# R40 register map
Vendor: Allwinner; Series: R40; File version: 0.1
CPU: CA7 0, little endian, MPU, FPU, double-precision FPU, 0 interrupt priority bits
Registers are 32-bit, read-write, reset 0x0 unless marked. A register's access mark holds for its fields unless they carry their own. Offsets are from the block's base; [hi:lo] are bit positions; {n}, {i} and the like mark numbered series.

## PIO
Base 0x01C20800
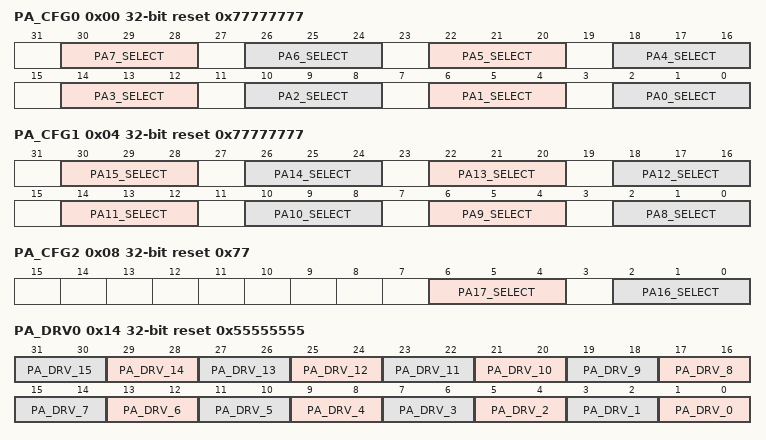
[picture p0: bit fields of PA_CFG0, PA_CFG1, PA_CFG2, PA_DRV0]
0x00 PA_CFG0 reset 0x77777777
  [30:28] PA7_SELECT — 000: Input 001: Output 010: ETXD0 011: SPI3_MOSI 100: Reserved 101: GTXD0 110: Reserved 111: IO Disable
    0=Input; 1=Output; 2=ETXD0; 3=SPI3_MOSI; 5=GTXD0; 7=IO (IO Disable)
  [26:24] PA6_SELECT — 000: Input 001: Output 010: ETXD1 011: SPI3_CLK 100: Reserved 101: GTXD1 110: Reserved 111: IO Disable
    0=Input; 1=Output; 2=ETXD1; 3=SPI3_CLK; 5=GTXD1; 7=IO (IO Disable)
  [22:20] PA5_SELECT — 000: Input 001: Output 010: ETXD2 011: SPI3_CS0 100: Reserved 101: GTXD2 110: Reserved 111: IO Disable
    0=Input; 1=Output; 2=ETXD2; 3=SPI3_CS0; 5=GTXD2; 7=IO (IO Disable)
  [18:16] PA4_SELECT — 000: Input 001: Output 010: ETXD3 011: SPI1_CS1 100: Reserved 101: GTXD3 110: Reserved 111: IO Disable
    0=Input; 1=Output; 2=ETXD3; 3=SPI1_CS1; 5=GTXD3; 7=IO (IO Disable)
  [14:12] PA3_SELECT — 000: Input 001: Output 010: ERXD0 011: SPI1_MISO 100: UART2_RX 101: GRXD0 110: Reserved 111: IO Disable
    0=Input; 1=Output; 2=ERXD0; 3=SPI1_MISO; 4=UART2_RX; 5=GRXD0; 7=IO (IO Disable)
  [10:8] PA2_SELECT — 000: Input 001: Output 010: ERXD1 011: SPI1_MOSI 100: UART2_TX 101: GRXD1 110: Reserved 111: IO Disable
    0=Input; 1=Output; 2=ERXD1; 3=SPI1_MOSI; 4=UART2_TX; 5=GRXD1; 7=IO (IO Disable)
  [6:4] PA1_SELECT — 000: Input 001: Output 010: ERXD2 011: SPI1_CLK 100: UART2_CTS 101: GRXD2 110: Reserved 111: IO Disable
    0=Input; 1=Output; 2=ERXD2; 3=SPI1_CLK; 4=UART2_CTS; 5=GRXD2; 7=IO (IO Disable)
  [2:0] PA0_SELECT — 000: Input 001: Output 010: ERXD3 011: SPI1_CS0 100: UART2_RTS 101: GRXD3 110: Reserved 111: IO Disable
    0=Input; 1=Output; 2=ERXD3; 3=SPI1_CS0; 4=UART2_RTS; 5=GRXD3; 7=IO (IO Disable)
0x04 PA_CFG1 reset 0x77777777
  [30:28] PA15_SELECT — 000: Input 001: Output 010: ECRS 011: UART7_RX 100: UART1_DSR 101: GTXCK/ECRS 110: I2S1_LRCK 111: IO Disable
    0=Input; 1=Output; 2=ECRS; 3=UART7_RX; 4=UART1_DSR; 5=GTXCK_slash_ECRS (GTXCK/ECRS); 6=I2S1_LRCK; 7=IO (IO Disable)
  [26:24] PA14_SELECT — 000: Input 001: Output 010: ETXCK 011: UART7_TX 100: UART1_DTR 101: GNULL/ETXCK 110: I2S1_BCLK 111: IO Disable
    0=Input; 1=Output; 2=ETXCK; 3=UART7_TX; 4=UART1_DTR; 5=GNULL_slash_ETXCK (GNULL/ETXCK); 6=I2S1_BCLK; 7=IO (IO Disable)
  [22:20] PA13_SELECT — 000: Input 001: Output 010: ETXEN 011: UART6_RX 100: UART1_CTS 101: GTXCTL/ETXEN 110: Reserved 111: IO Disable
    0=Input; 1=Output; 2=ETXEN; 3=UART6_RX; 4=UART1_CTS; 5=GTXCTL_slash_ETXEN (GTXCTL/ETXEN); 7=IO (IO Disable)
  [18:16] PA12_SELECT — 000: Input 001: Output 010: EMDIO 011: UART6_TX 100: UART1_RTS 101: GMDIO 110: Reserved 111: IO Disable
    0=Input; 1=Output; 2=EMDIO; 3=UART6_TX; 4=UART1_RTS; 5=GMDIO; 7=IO (IO Disable)
  [14:12] PA11_SELECT — 000: Input 001: Output 010: EMDC 011: Reserved 100: UART1_RX 101: GMDC 110: Reserved 111: IO Disable
    0=Input; 1=Output; 2=EMDC; 4=UART1_RX; 5=GMDC; 7=IO (IO Disable)
  [10:8] PA10_SELECT — 000: Input 001: Output 010: ERXDV 011: Reserved 100: UART1_TX 101: GRXCTL/ERXDV 110: Reserved 111: IO Disable
    0=Input; 1=Output; 2=ERXDV; 4=UART1_TX; 5=GRXCTL_slash_ERXDV (GRXCTL/ERXDV); 7=IO (IO Disable)
  [6:4] PA9_SELECT — 000: Input 001: Output 010: ERXERR 011: SPI3_CS1 100: Reserved 101: GNULL/ERXERR 110: I2S1_MCLK 111: IO Disable
    0=Input; 1=Output; 2=ERXERR; 3=SPI3_CS1; 5=GNULL_slash_ERXERR (GNULL/ERXERR); 6=I2S1_MCLK; 7=IO (IO Disable)
  [2:0] PA8_SELECT — 000: Input 001: Output 010: ERXCK 011: SPI3_MISO 100: Reserved 101: GRXCK 110: Reserved 111: IO Disable
    0=Input; 1=Output; 2=ERXCK; 3=SPI3_MISO; 5=GRXCK; 7=IO (IO Disable)
0x08 PA_CFG2 reset 0x77
  [6:4] PA17_SELECT — 000: Input 001: Output 010: ETXERR 011: Reserved 100: UART1_RING 101: GNULL/ETXERR 110: I2S1_DI 111: IO Disable
    0=Input; 1=Output; 2=ETXERR; 4=UART1_RING; 5=GNULL_slash_ETXERR (GNULL/ETXERR); 6=I2S1_DI; 7=IO (IO Disable)
  [2:0] PA16_SELECT — 000: Input 001: Output 010: ECOL 011: Reserved 100: UART1_DCD 101: GCLKIN/ECOL 110: I2S1_DO 111: IO Disable
    0=Input; 1=Output; 2=ECOL; 4=UART1_DCD; 5=GCLKIN_slash_ECOL (GCLKIN/ECOL); 6=I2S1_DO; 7=IO (IO Disable)
0x0C PA_CFG3 reset not defined
0x10 PA_DAT
  [17:0] PA_DAT — If the port is configured as input, the corresponding bit is the pin state. If the port is configured as output, the pin state is the same as the corresponding bit. The read bit value is the value setup by software. If the port is configured as functional pin, the undefined value will be read.
0x14 PA_DRV0 reset 0x55555555
  [2n+1:2n] PA_DRV_{n} (n=0..15) — PA[n] Multi-Driving Select (n = 0~15) 00: Level 0 01: Level 1 10: Level 2 11: Level 3
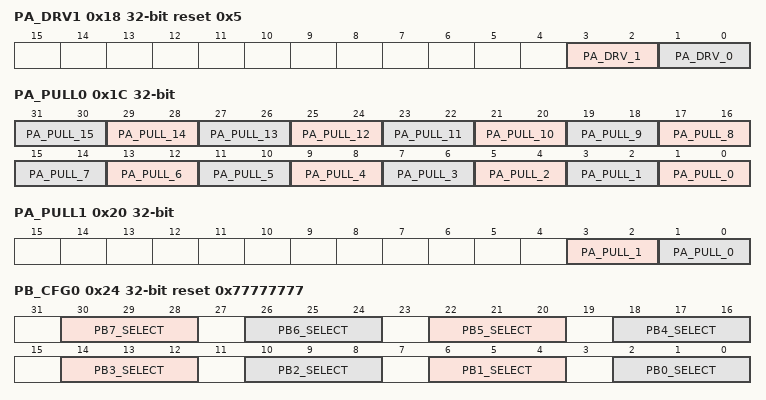
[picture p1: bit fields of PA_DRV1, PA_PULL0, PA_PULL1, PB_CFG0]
0x18 PA_DRV1 reset 0x5
  [3:2] PA_DRV_1 — PA[n] Multi-Driving Select (n = 16~17) 00: Level 0 01: Level 1 10: Level 2 11: Level 3
  [1:0] PA_DRV_0 — PA[n] Multi-Driving Select (n = 16~17) 00: Level 0 01: Level 1 10: Level 2 11: Level 3
0x1C PA_PULL0
  [2n+1:2n] PA_PULL_{n} (n=0..15) — PA[n] Pull-up/down Select (n = 0~15) 00: Pull-up/down disable 01: Pull-up 10: Pull-down 11: Reserved
0x20 PA_PULL1
  [3:2] PA_PULL_1 — PA[n] Pull-up/down Select (n = 16~17) 00: Pull-up/down disable 01: Pull-up enable 10: Pull-down 11: Reserved
  [1:0] PA_PULL_0 — PA[n] Pull-up/down Select (n = 16~17) 00: Pull-up/down disable 01: Pull-up enable 10: Pull-down 11: Reserved
0x24 PB_CFG0 reset 0x77777777
  [30:28] PB7_SELECT — 000: Input 001: Output 010: I2S_LRCK 011: AC97_SYNC 100: Reserved 101: Reserved 110: Reserved 111: IO Disable
    0=Input; 1=Output; 2=I2S_LRCK; 3=AC97_SYNC; 7=IO (IO Disable)
  [26:24] PB6_SELECT — 000: Input 001: Output 010: I2S_BCLK 011: AC97_BCLK 100: Reserved 101: Reserved 110: Reserved 111: IO Disable
    0=Input; 1=Output; 2=I2S_BCLK; 3=AC97_BCLK; 7=IO (IO Disable)
  [22:20] PB5_SELECT — 000: Input 001: Output 010: I2S_MCLK 011: AC97_MCLK 100: Reserved 101: Reserved 110: Reserved 111: IO Disable
    0=Input; 1=Output; 2=I2S_MCLK; 3=AC97_MCLK; 7=IO (IO Disable)
  [18:16] PB4_SELECT — 000: Input 001: Output 010: CIR0_RX 011: Reserved 100: Reserved 101: Reserved 110: Reserved 111: IO Disable
    0=Input; 1=Output; 2=CIR0_RX; 7=IO (IO Disable)
  [14:12] PB3_SELECT — 000: Input 001: Output 010: Reserved 011: PWM1 100: OWA_MCLK 101: Reserved 110: Reserved 111: IO Disable
    0=Input; 1=Output; 3=PWM1; 4=OWA_MCLK; 7=IO (IO Disable)
  [10:8] PB2_SELECT — 000: Input 001: Output 010: Reserved 011: PWM0 100: Reserved 101: Reserved 110: Reserved 111: IO Disable
    0=Input; 1=Output; 3=PWM0; 7=IO (IO Disable)
  [6:4] PB1_SELECT — 000: Input 001: Output 010: TWI0_SDA 011: Reserved 100: Reserved 101: Reserved 110: Reserved 111: IO Disable
    0=Input; 1=Output; 2=TWI0_SDA; 7=IO (IO Disable)
  [2:0] PB0_SELECT — 000: Input 001: Output 010: TWI0_SCK 011: PLL_LOCK_DBG 100: Reserved 101: Reserved 110: Reserved 111: IO Disable
    0=Input; 1=Output; 2=TWI0_SCK; 3=PLL_LOCK_DBG; 7=IO (IO Disable)
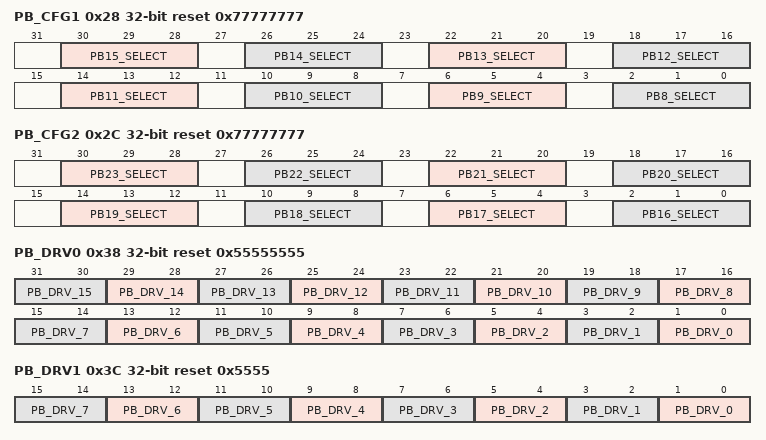
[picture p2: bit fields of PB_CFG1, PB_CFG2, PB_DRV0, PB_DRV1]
0x28 PB_CFG1 reset 0x77777777
  [30:28] PB15_SELECT — 000: Input 001: Output 010: SPI2_CLK 011: JTAG_CK0 100: Reserved 101: Reserved 110: Reserved 111: IO Disable
    0=Input; 1=Output; 2=SPI2_CLK; 3=JTAG_CK0; 7=IO (IO Disable)
  [26:24] PB14_SELECT — 000: Input 001: Output 010: SPI2_CS0 011: JTAG_MS0 100: Reserved 101: Reserved 110: Reserved 111: IO Disable
    0=Input; 1=Output; 2=SPI2_CS0; 3=JTAG_MS0; 7=IO (IO Disable)
  [22:20] PB13_SELECT — 000: Input 001: Output 010: SPI2_CS1 011: Reserved 100: OWA_DO 101: Reserved 110: Reserved 111: IO Disable
    0=Input; 1=Output; 2=SPI2_CS1; 4=OWA_DO; 7=IO (IO Disable)
  [18:16] PB12_SELECT — 000: Input 001: Output 010: I2S_DI 011: AC97_DI 100: Reserved 101: Reserved 110: Reserved 111: IO Disable
    0=Input; 1=Output; 2=I2S_DI; 3=AC97_DI; 7=IO (IO Disable)
  [14:12] PB11_SELECT — 000: Input 001: Output 010: I2S_DO3 011: Reserved 100: Reserved 101: Reserved 110: Reserved 111: IO Disable
    0=Input; 1=Output; 2=I2S_DO3; 7=IO (IO Disable)
  [10:8] PB10_SELECT — 000: Input 001: Output 010: I2S_DO2 011: Reserved 100: PWM7 101: Reserved 110: Reserved 111: IO Disable
    0=Input; 1=Output; 2=I2S_DO2; 4=PWM7; 7=IO (IO Disable)
  [6:4] PB9_SELECT — 000: Input 001: Output 010: I2S_DO1 011: Reserved 100: PWM6 101: Reserved 110: Reserved 111: IO Disable
    0=Input; 1=Output; 2=I2S_DO1; 4=PWM6; 7=IO (IO Disable)
  [2:0] PB8_SELECT — 000: Input 001: Output 010: I2S_DO0 011: AC97_DO 100: Reserved 101: Reserved 110: Reserved 111: IO Disable
    0=Input; 1=Output; 2=I2S_DO0; 3=AC97_DO; 7=IO (IO Disable)
0x2C PB_CFG2 reset 0x77777777
  [30:28] PB23_SELECT — 000: Input 001: Output 010: UART0_RX 011: CIR1_RX 100: Reserved 101: Reserved 110: Reserved 111: IO Disable
    0=Input; 1=Output; 2=UART0_RX; 3=CIR1_RX; 7=IO (IO Disable)
  [26:24] PB22_SELECT — 000: Input 001: Output 010: UART0_TX 011: Reserved 100: Reserved 101: Reserved 110: Reserved 111: IO Disable
    0=Input; 1=Output; 2=UART0_TX; 7=IO (IO Disable)
  [22:20] PB21_SELECT — 000: Input 001: Output 010: TWI2_SDA 011: Reserved 100: PWM5 101: Reserved 110: Reserved 111: IO Disable
    0=Input; 1=Output; 2=TWI2_SDA; 4=PWM5; 7=IO (IO Disable)
  [18:16] PB20_SELECT — 000: Input 001: Output 010: TWI2_SCK 011: Reserved 100: PWM4 101: Reserved 110: Reserved 111: IO Disable
    0=Input; 1=Output; 2=TWI2_SCK; 4=PWM4; 7=IO (IO Disable)
  [14:12] PB19_SELECT — 000: Input 001: Output 010: TWI1_SDA 011: Reserved 100: Reserved 101: Reserved 110: Reserved 111: IO Disable
    0=Input; 1=Output; 2=TWI1_SDA; 7=IO (IO Disable)
  [10:8] PB18_SELECT — 000: Input 001: Output 010: TWI1_SCK 011: Reserved 100: Reserved 101: Reserved 110: Reserved 111: IO Disable
    0=Input; 1=Output; 2=TWI1_SCK; 7=IO (IO Disable)
  [6:4] PB17_SELECT — 000: Input 001: Output 010: SPI2_MISO 011: JTAG_DI0 100: Reserved 101: Reserved 110: Reserved 111: IO Disable
    0=Input; 1=Output; 2=SPI2_MISO; 3=JTAG_DI0; 7=IO (IO Disable)
  [2:0] PB16_SELECT — 000: Input 001: Output 010: SPI2_MOSI 011: JTAG_DO0 100: Reserved 101: Reserved 110: Reserved 111: IO Disable
    0=Input; 1=Output; 2=SPI2_MOSI; 3=JTAG_DO0; 7=IO (IO Disable)
0x30 PB_CFG3 reset not defined
0x34 PB_DAT
  [23:0] PB_DAT — If the port is configured as input, the corresponding bit is the pin state. If the port is configured as output, the pin state is the same as the corresponding bit. The read bit value is the value setup by software. If the port is configured as functional pin, the undefined value will be read.
0x38 PB_DRV0 reset 0x55555555
  [2n+1:2n] PB_DRV_{n} (n=0..15) — PB[n] Multi-Driving Select (n = 0~15) 00: Level 0 01: Level 1 10: Level 2 11: Level 3
0x3C PB_DRV1 reset 0x5555
  [2n+1:2n] PB_DRV_{n} (n=0..7) — PB[n] Multi-Driving Select (n = 16~23) 00: Level 0 01: Level 1 10: Level 2 11: Level 3
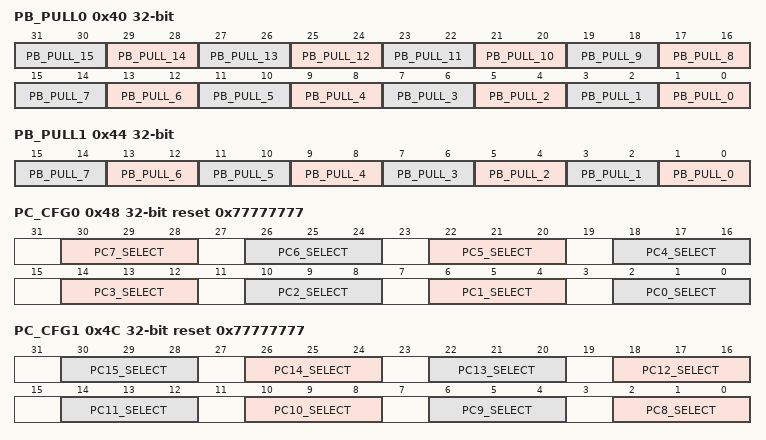
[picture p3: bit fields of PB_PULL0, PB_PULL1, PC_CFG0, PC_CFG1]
0x40 PB_PULL0
  [2n+1:2n] PB_PULL_{n} (n=0..15) — PB[n] Pull-up/down Select (n = 0~15) 00: Pull-up/down disable 01: Pull-up 10: Pull-down 11: Reserved
0x44 PB_PULL1
  [2n+1:2n] PB_PULL_{n} (n=0..7) — PB[n] Pull-up/down Select (n = 16~23) 00: Pull-up/down disable 01: Pull-up 10: Pull-down 11: Reserved
0x48 PC_CFG0 reset 0x77777777
  [30:28] PC7_SELECT — 000: Input 001: Output 010: NRB1 011: SDC2_CLK 100: Reserved 101: Reserved 110: Reserved 111: IO Disable
    0=Input; 1=Output; 2=NRB1; 3=SDC2_CLK; 7=IO (IO Disable)
  [26:24] PC6_SELECT — 000: Input 001: Output 010: NRB0 011: SDC2_CMD 100: Reserved 101: Reserved 110: Reserved 111: IO Disable
    0=Input; 1=Output; 2=NRB0; 3=SDC2_CMD; 7=IO (IO Disable)
  [22:20] PC5_SELECT — 000: Input 001: Output 010: NRE 011: SDC2_DS 100: Reserved 101: Reserved 110: Reserved 111: IO Disable
    0=Input; 1=Output; 2=NRE; 3=SDC2_DS; 7=IO (IO Disable)
  [18:16] PC4_SELECT — 000: Input 001: Output 010: NCE0 011: Reserved 100: Reserved 101: Reserved 110: Reserved 111: IO Disable
    0=Input; 1=Output; 2=NCE0; 7=IO (IO Disable)
  [14:12] PC3_SELECT — 000: Input 001: Output 010: NCE1 011: Reserved 100: Reserved 101: Reserved 110: Reserved 111: IO Disable
    0=Input; 1=Output; 2=NCE1; 7=IO (IO Disable)
  [10:8] PC2_SELECT — 000: Input 001: Output 010: NCLE 011: SPI0_CLK 100: Reserved 101: Reserved 110: Reserved 111: IO Disable
    0=Input; 1=Output; 2=NCLE; 3=SPI0_CLK; 7=IO (IO Disable)
  [6:4] PC1_SELECT — 000: Input 001: Output 010: NALE 011: SPI0_MISO 100: Reserved 101: Reserved 110: Reserved 111: IO Disable
    0=Input; 1=Output; 2=NALE; 3=SPI0_MISO; 7=IO (IO Disable)
  [2:0] PC0_SELECT — 000: Input 001: Output 010: NWE 011: SPI0_MOSI 100: Reserved 101: Reserved 110: Reserved 111: IO Disable
    0=Input; 1=Output; 2=NWE; 3=SPI0_MOSI; 7=IO (IO Disable)
0x4C PC_CFG1 reset 0x77777777
  [4n-30:4n-32] PC{n}_SELECT (n=8..15) — 000: Input 001: Output 010: NDQ{n-8} 011: SDC2_D{n-8} 100: Reserved 101: Reserved 110: Reserved 111: IO Disable
    0=Input; 1=Output; 2=NDQ{n-8}; 3=SDC2_D{n-8}; 7=IO (IO Disable)
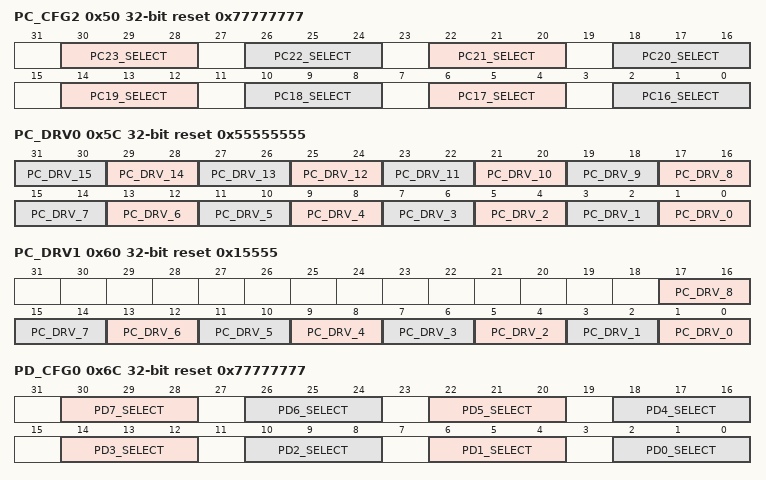
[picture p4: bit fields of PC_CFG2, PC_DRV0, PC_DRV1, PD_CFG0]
0x50 PC_CFG2 reset 0x77777777
  [30:28] PC23_SELECT — 000: Input 001: Output 010: Reserved 011: SPI0_CS0 100: Reserved 101: Reserved 110: Reserved 111: IO Disable
    0=Input; 1=Output; 3=SPI0_CS0; 7=IO (IO Disable)
  [26:24] PC22_SELECT — 000: Input 001: Output 010: NCE7 011: SPI2_MISO 100: Reserved 101: Reserved 110: Reserved 111: IO Disable
    0=Input; 1=Output; 2=NCE7; 3=SPI2_MISO; 7=IO (IO Disable)
  [22:20] PC21_SELECT — 000: Input 001: Output 010: NCE6 011: SPI2_MOSI 100: Reserved 101: Reserved 110: Reserved 111: IO Disable
    0=Input; 1=Output; 2=NCE6; 3=SPI2_MOSI; 7=IO (IO Disable)
  [18:16] PC20_SELECT — 000: Input 001: Output 010: NCE5 011: SPI2_CLK 100: Reserved 101: Reserved 110: Reserved 111: IO Disable
    0=Input; 1=Output; 2=NCE5; 3=SPI2_CLK; 7=IO (IO Disable)
  [14:12] PC19_SELECT — 000: Input 001: Output 010: NCE4 011: SPI2_CS0 100: Reserved 101: Reserved 110: Reserved 111: IO Disable
    0=Input; 1=Output; 2=NCE4; 3=SPI2_CS0; 7=IO (IO Disable)
  [10:8] PC18_SELECT — 000: Input 001: Output 010: NCE3 011: Reserved 100: Reserved 101: Reserved 110: Reserved 111: IO Disable
    0=Input; 1=Output; 2=NCE3; 7=IO (IO Disable)
  [6:4] PC17_SELECT — 000: Input 001: Output 010: NCE2 011: Reserved 100: Reserved 101: Reserved 110: Reserved 111: IO Disable
    0=Input; 1=Output; 2=NCE2; 7=IO (IO Disable)
  [2:0] PC16_SELECT — 000: Input 001: Output 010: NWP 011: Reserved 100: Reserved 101: Reserved 110: Reserved 111: IO Disable
    0=Input; 1=Output; 2=NWP; 7=IO (IO Disable)
0x54 PC_CFG3 reset 0x7
  [2:0] PC24_SELECT — 000: Input 001: Output 010: NDQS 011: SDC2_RST 100: Reserved 101: Reserved 110: Reserved 111: IO Disable
    0=Input; 1=Output; 2=NDQS; 3=SDC2_RST; 7=IO (IO Disable)
0x58 PC_DAT
  [23:0] PC_DAT — If the port is configured as input, the corresponding bit is the pin state. If the port is configured as output, the pin state is the same as the corresponding bit. The read bit value is the value setup by software. If the port is configured as functional pin, the undefined value will be read.
0x5C PC_DRV0 reset 0x55555555
  [2n+1:2n] PC_DRV_{n} (n=0..15) — PC[n] Multi-Driving Select (n = 0~15) 00: Level 0 01: Level 1 10: Level 2 11: Level 3
0x60 PC_DRV1 reset 0x15555
  [2n+1:2n] PC_DRV_{n} (n=0..8) — PC[n] Multi-Driving Select (n = 16~24) 00: Level 0 01: Level 1 10: Level 2 11: Level 3
0x64 PC_PULL0 reset not defined
0x68 PC_PULL1 reset not defined
0x6C PD_CFG0 reset 0x77777777
  [30:28] PD7_SELECT — 000: Input 001: Output 010: LCD0_D7 011: LVDS0_VNC 100: Reserved 101: Reserved 110: Reserved 111: IO Disable
    0=Input; 1=Output; 2=LCD0_D7; 3=LVDS0_VNC; 7=IO (IO Disable)
  [26:24] PD6_SELECT — 000: Input 001: Output 010: LCD0_D6 011: LVDS0_VPC 100: Reserved 101: Reserved 110: Reserved 111: IO Disable
    0=Input; 1=Output; 2=LCD0_D6; 3=LVDS0_VPC; 7=IO (IO Disable)
  [22:20] PD5_SELECT — 000: Input 001: Output 010: LCD0_D5 011: LVDS0_VN2 100: Reserved 101: Reserved 110: Reserved 111: IO Disable
    0=Input; 1=Output; 2=LCD0_D5; 3=LVDS0_VN2; 7=IO (IO Disable)
  [18:16] PD4_SELECT — 000: Input 001: Output 010: LCD0_D4 011: LVDS0_VP2 100: Reserved 101: Reserved 110: Reserved 111: IO Disable
    0=Input; 1=Output; 2=LCD0_D4; 3=LVDS0_VP2; 7=IO (IO Disable)
  [14:12] PD3_SELECT — 000: Input 001: Output 010: LCD0_D3 011: LVDS0_VN1 100: Reserved 101: Reserved 110: Reserved 111: IO Disable
    0=Input; 1=Output; 2=LCD0_D3; 3=LVDS0_VN1; 7=IO (IO Disable)
  [10:8] PD2_SELECT — 000: Input 001: Output 010: LCD0_D2 011: LVDS0_VP1 100: Reserved 101: Reserved 110: Reserved 111: IO Disable
    0=Input; 1=Output; 2=LCD0_D2; 3=LVDS0_VP1; 7=IO (IO Disable)
  [6:4] PD1_SELECT — 000: Input 001: Output 010: LCD0_D1 011: LVDS0_VN0 100: Reserved 101: Reserved 110: Reserved 111: IO Disable
    0=Input; 1=Output; 2=LCD0_D1; 3=LVDS0_VN0; 7=IO (IO Disable)
  [2:0] PD0_SELECT — 000: Input 001: Output 010: LCD0_D0 011: LVDS0_VP0 100: Reserved 101: Reserved 110: Reserved 111: IO Disable
    0=Input; 1=Output; 2=LCD0_D0; 3=LVDS0_VP0; 7=IO (IO Disable)
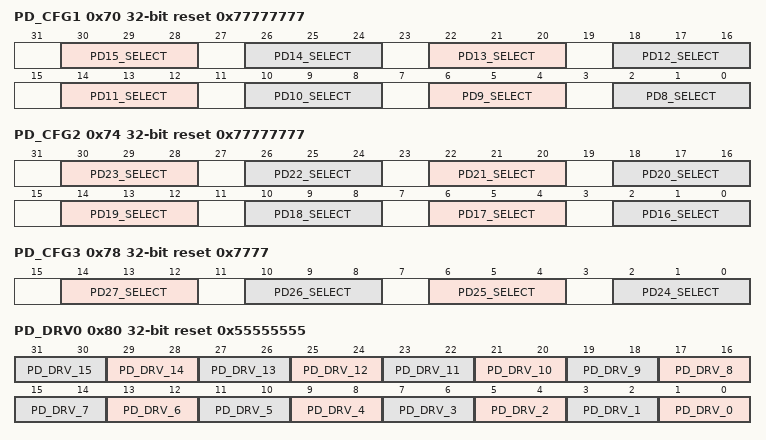
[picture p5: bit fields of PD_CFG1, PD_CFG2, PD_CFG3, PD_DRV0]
0x70 PD_CFG1 reset 0x77777777
  [30:28] PD15_SELECT — 000: Input 001: Output 010: LCD0_D15 011: LVDS1_VN2 100: Reserved 101: Reserved 110: Reserved 111: IO Disable
    0=Input; 1=Output; 2=LCD0_D15; 3=LVDS1_VN2; 7=IO (IO Disable)
  [26:24] PD14_SELECT — 000: Input 001: Output 010: LCD0_D14 011: LVDS1_VP2 100: Reserved 101: Reserved 110: Reserved 111: IO Disable
    0=Input; 1=Output; 2=LCD0_D14; 3=LVDS1_VP2; 7=IO (IO Disable)
  [22:20] PD13_SELECT — 000: Input 001: Output 010: LCD0_D13 011: LVDS1_VN1 100: Reserved 101: Reserved 110: Reserved 111: IO Disable
    0=Input; 1=Output; 2=LCD0_D13; 3=LVDS1_VN1; 7=IO (IO Disable)
  [18:16] PD12_SELECT — 000: Input 001: Output 010: LCD0_D12 011: LVDS1_VP1 100: Reserved 101: Reserved 110: Reserved 111: IO Disable
    0=Input; 1=Output; 2=LCD0_D12; 3=LVDS1_VP1; 7=IO (IO Disable)
  [14:12] PD11_SELECT — 000: Input 001: Output 010: LCD0_D11 011: LVDS1_VN0 100: Reserved 101: Reserved 110: Reserved 111: IO Disable
    0=Input; 1=Output; 2=LCD0_D11; 3=LVDS1_VN0; 7=IO (IO Disable)
  [10:8] PD10_SELECT — 000: Input 001: Output 010: LCD0_D10 011: LVDS1_VP0 100: Reserved 101: Reserved 110: Reserved 111: IO Disable
    0=Input; 1=Output; 2=LCD0_D10; 3=LVDS1_VP0; 7=IO (IO Disable)
  [6:4] PD9_SELECT — 000: Input 001: Output 010: LCD0_D9 011: LVDS0_VN3 100: Reserved 101: Reserved 110: Reserved 111: IO Disable
    0=Input; 1=Output; 2=LCD0_D9; 3=LVDS0_VN3; 7=IO (IO Disable)
  [2:0] PD8_SELECT — 000: Input 001: Output 010: LCD0_D8 011: LVDS0_VP3 100: Reserved 101: Reserved 110: Reserved 111: IO Disable
    0=Input; 1=Output; 2=LCD0_D8; 3=LVDS0_VP3; 7=IO (IO Disable)
0x74 PD_CFG2 reset 0x77777777
  [30:28] PD23_SELECT — 000: Input 001: Output 010: LCD0_D23 011: SMC_DET 100: Reserved 101: Reserved 110: Reserved 111: IO Disable
    0=Input; 1=Output; 2=LCD0_D23; 3=SMC_DET; 7=IO (IO Disable)
  [26:24] PD22_SELECT — 000: Input 001: Output 010: LCD0_D22 011: SMC_VPPPP 100: Reserved 101: Reserved 110: Reserved 111: IO Disable
    0=Input; 1=Output; 2=LCD0_D22; 3=SMC_VPPPP; 7=IO (IO Disable)
  [22:20] PD21_SELECT — 000: Input 001: Output 010: LCD0_D21 011: SMC_VPPEN 100: Reserved 101: Reserved 110: Reserved 111: IO Disable
    0=Input; 1=Output; 2=LCD0_D21; 3=SMC_VPPEN; 7=IO (IO Disable)
  [18:16] PD20_SELECT — 000: Input 001: Output 010: LCD0_D20 011: CSI1_MCLK 100: Reserved 101: Reserved 110: Reserved 111: Reserved
    0=Input; 1=Output; 2=LCD0_D20; 3=CSI1_MCLK
  [14:12] PD19_SELECT — 000: Input 001: Output 010: LCD0_D19 011: LVDS1_VN3 100: Reserved 101: Reserved 110: Reserved 111: IO Disable
    0=Input; 1=Output; 2=LCD0_D19; 3=LVDS1_VN3; 7=IO (IO Disable)
  [10:8] PD18_SELECT — 000: Input 001: Output 010: LCD0_D18 011: LVDS1_VP3 100: Reserved 101: Reserved 110: Reserved 111: IO Disable
    0=Input; 1=Output; 2=LCD0_D18; 3=LVDS1_VP3; 7=IO (IO Disable)
  [6:4] PD17_SELECT — 000: Input 001: Output 010: LCD0_D17 011: LVDS1_VNC 100: Reserved 101: Reserved 110: Reserved 111: IO Disable
    0=Input; 1=Output; 2=LCD0_D17; 3=LVDS1_VNC; 7=IO (IO Disable)
  [2:0] PD16_SELECT — 000: Input 001: Output 010: LCD0_D16 011: LVDS1_VPC 100: Reserved 101: Reserved 110: Reserved 111: IO Disable
    0=Input; 1=Output; 2=LCD0_D16; 3=LVDS1_VPC; 7=IO (IO Disable)
0x78 PD_CFG3 reset 0x7777
  [14:12] PD27_SELECT — 000: Input 001: Output 010: LCD0_VSYNC 011: SMC_SDA 100: Reserved 101: Reserved 110: Reserved 111: IO Disable
    0=Input; 1=Output; 2=LCD0_VSYNC; 3=SMC_SDA; 7=IO (IO Disable)
  [10:8] PD26_SELECT — 000: Input 001: Output 010: LCD0_HSYNC 011: SMC_SLK 100: Reserved 101: Reserved 110: Reserved 111: IO Disable
    0=Input; 1=Output; 2=LCD0_HSYNC; 3=SMC_SLK; 7=IO (IO Disable)
  [6:4] PD25_SELECT — 000: Input 001: Output 010: LCD0_DE 011: SMC_RST 100: Reserved 101: Reserved 110: Reserved 111: IO Disable
    0=Input; 1=Output; 2=LCD0_DE; 3=SMC_RST; 7=IO (IO Disable)
  [2:0] PD24_SELECT — 000: Input 001: Output 010: LCD0_CLK 011: SMC_VCCEN 100: Reserved 101: Reserved 110: Reserved 111: IO Disable
    0=Input; 1=Output; 2=LCD0_CLK; 3=SMC_VCCEN; 7=IO (IO Disable)
0x7C PD_DAT
  [27:0] PD_DAT — If the port is configured as input, the corresponding bit is the pin state. If the port is configured as output, the pin state is the same as the corresponding bit. The read bit value is the value setup by software. If the port is configured as functional pin, the undefined value will be read.
0x80 PD_DRV0 reset 0x55555555
  [2n+1:2n] PD_DRV_{n} (n=0..15) — PD[n] Multi-Driving Select (n = 0~15) 00: Level 0 01: Level 1 10: Level 2 11: Level 3
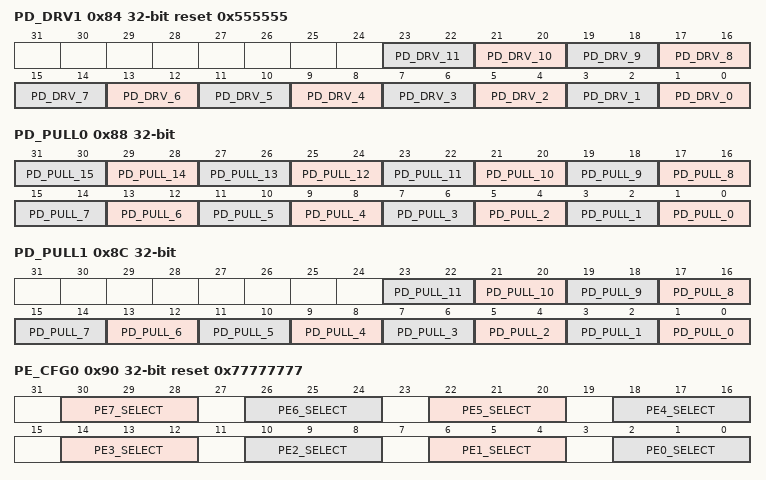
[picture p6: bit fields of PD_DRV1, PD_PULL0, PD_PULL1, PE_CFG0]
0x84 PD_DRV1 reset 0x555555
  [2n+1:2n] PD_DRV_{n} (n=0..11) — PD[n] Multi-Driving Select (n = 16~27) 00: Level 0 01: Level 1 10: Level 2 11: Level 3
0x88 PD_PULL0
  [2n+1:2n] PD_PULL_{n} (n=0..15) — PD[n] Pull-up/down Select (n = 0~15) 00: Pull-up/down disable 01: Pull-up 10: Pull-down 11: Reserved
0x8C PD_PULL1
  [2n+1:2n] PD_PULL_{n} (n=0..11) — PD[n] Pull-up/down Select (n = 16~27) 00: Pull-up/down disable 01: Pull-up 10: Pull-down 11: Reserved
0x90 PE_CFG0 reset 0x77777777
  [30:28] PE7_SELECT — 000: Input 001: Output 010: TS0_D3 011: CSI0_D3 100: Reserved 101: Reserved 110: Reserved 111: IO Disable
    0=Input; 1=Output; 2=TS0_D3; 3=CSI0_D3; 7=IO (IO Disable)
  [26:24] PE6_SELECT — 000: Input 001: Output 010: TS0_D2 011: CSI0_D2 100: Reserved 101: Reserved 110: Reserved 111: IO Disable
    0=Input; 1=Output; 2=TS0_D2; 3=CSI0_D2; 7=IO (IO Disable)
  [22:20] PE5_SELECT — 000: Input 001: Output 010: TS0_D1 011: CSI0_D1 100: SMC_VPPEN 101: Reserved 110: Reserved 111: IO Disable
    0=Input; 1=Output; 2=TS0_D1; 3=CSI0_D1; 4=SMC_VPPEN; 7=IO (IO Disable)
  [18:16] PE4_SELECT — 000: Input 001: Output 010: TS0_D0 011: CSI0_D0 100: Reserved 101: Reserved 110: Reserved 111: IO Disable
    0=Input; 1=Output; 2=TS0_D0; 3=CSI0_D0; 7=IO (IO Disable)
  [14:12] PE3_SELECT — 000: Input 001: Output 010: TS0_DVLD 011: CSI0_VSYNC 100: Reserved 101: Reserved 110: Reserved 111: IO Disable
    0=Input; 1=Output; 2=TS0_DVLD; 3=CSI0_VSYNC; 7=IO (IO Disable)
  [10:8] PE2_SELECT — 000: Input 001: Output 010: TS0_SYNC 011: CSI0_HSYNC 100: Reserved 101: Reserved 110: Reserved 111: IO Disable
    0=Input; 1=Output; 2=TS0_SYNC; 3=CSI0_HSYNC; 7=IO (IO Disable)
  [6:4] PE1_SELECT — 000: Input 001: Output 010: TS0_ERR 011: CSI0_MCLK 100: Reserved 101: Reserved 110: Reserved 111: IO Disable
    0=Input; 1=Output; 2=TS0_ERR; 3=CSI0_MCLK; 7=IO (IO Disable)
  [2:0] PE0_SELECT — 000: Input 001: Output 010: TS0_CLK 011: CSI0_PCLK 100: Reserved 101: Reserved 110: Reserved 111: IO Disable
    0=Input; 1=Output; 2=TS0_CLK; 3=CSI0_PCLK; 7=IO (IO Disable)
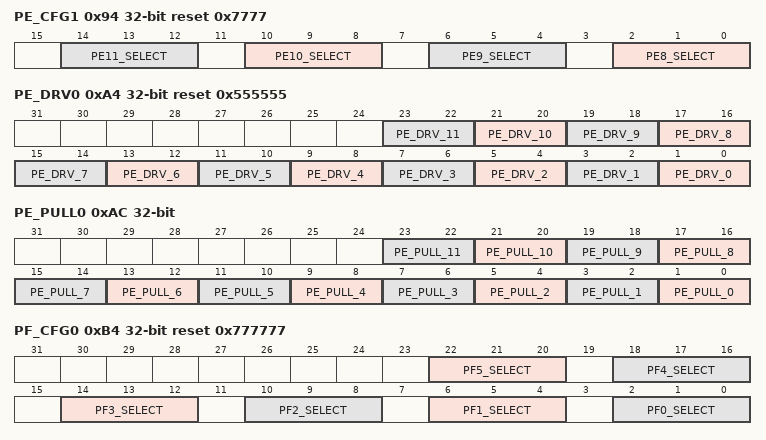
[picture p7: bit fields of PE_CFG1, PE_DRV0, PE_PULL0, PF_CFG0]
0x94 PE_CFG1 reset 0x7777
  [4n-30:4n-32] PE{n}_SELECT (n=8..11) — 000: Input 001: Output 010: TS0_D{n-4} 011: CSI0_D{n-4} 100: Reserved 101: Reserved 110: Reserved 111: IO Disable
    0=Input; 1=Output; 2=TS0_D{n-4}; 3=CSI0_D{n-4}; 7=IO (IO Disable)
0x98 PE_CFG2 reset not defined
0x9C PE_CFG3 reset not defined
0xA0 PE_DAT
  [11:0] PE_DAT — If the port is configured as input, the corresponding bit is the pin state. If the port is configured as output, the pin state is the same as the corresponding bit. The read bit value is the value setup by software. If the port is configured as functional pin, the undefined value will be read.
0xA4 PE_DRV0 reset 0x555555
  [2n+1:2n] PE_DRV_{n} (n=0..11) — PE[n] Multi-Driving Select (n = 0~11) 00: Level 0 01: Level 1 10: Level 2 11: Level 3
0xA8 PE_DRV1 reset not defined
0xAC PE_PULL0
  [2n+1:2n] PE_PULL_{n} (n=0..11) — PE[n] Pull-up/down Select (n = 0~11) 00: Pull-up/down disable 01: Pull-up 10: Pull-down 11: Reserved
0xB0 PE_PULL1 reset not defined
0xB4 PF_CFG0 reset 0x777777
  [22:20] PF5_SELECT — 000: Input 001: Output 010: SDC0_D2 011: Reserved 100: JTAG_CK1 101: Reserved 110: Reserved 111: IO Disable
    0=Input; 1=Output; 2=SDC0_D2; 4=JTAG_CK1; 7=IO (IO Disable)
  [18:16] PF4_SELECT — 000: Input 001: Output 010: SDC0_D3 011: Reserved 100: UART0_RX 101: Reserved 110: Reserved 111: IO Disable
    0=Input; 1=Output; 2=SDC0_D3; 4=UART0_RX; 7=IO (IO Disable)
  [14:12] PF3_SELECT — 000: Input 001: Output 010: SDC0_CMD 011: Reserved 100: JTAG_DO1 101: Reserved 110: Reserved 111: IO Disable
    0=Input; 1=Output; 2=SDC0_CMD; 4=JTAG_DO1; 7=IO (IO Disable)
  [10:8] PF2_SELECT — 000: Input 001: Output 010: SDC0_CLK 011: Reserved 100: UART0_TX 101: Reserved 110: Reserved 111: IO Disable
    0=Input; 1=Output; 2=SDC0_CLK; 4=UART0_TX; 7=IO (IO Disable)
  [6:4] PF1_SELECT — 000: Input 001: Output 010: SDC0_D0 011: Reserved 100: JTAG_DI1 101: Reserved 110: Reserved 111: IO Disable
    0=Input; 1=Output; 2=SDC0_D0; 4=JTAG_DI1; 7=IO (IO Disable)
  [2:0] PF0_SELECT — 000: Input 001: Output 010: SDC0_D1 011: Reserved 100: JTAG_MS1 101: Reserved 110: Reserved 111: IO Disable
    0=Input; 1=Output; 2=SDC0_D1; 4=JTAG_MS1; 7=IO (IO Disable)
{0xB4+4i} PF_CFG{i} reset not defined (i=1..3)
0xC4 PF_DAT
  [5:0] PF_DAT — If the port is configured as input, the corresponding bit is the pin state. If the port is configured as output, the pin state is the same as the corresponding bit. The read bit value is the value setup by software. If the port is configured as functional pin, the undefined value will be read.
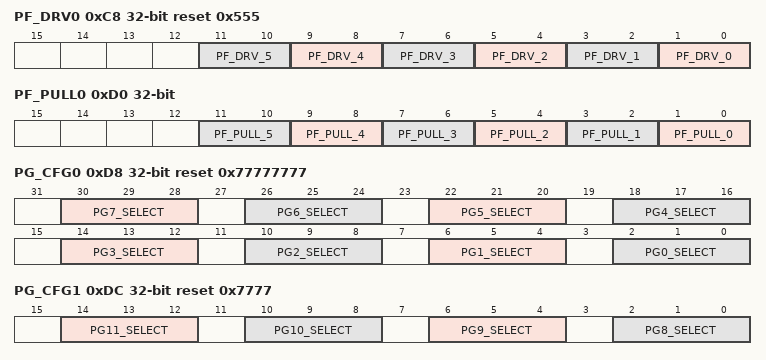
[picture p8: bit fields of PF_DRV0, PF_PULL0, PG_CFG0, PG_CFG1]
0xC8 PF_DRV0 reset 0x555
  [2n+1:2n] PF_DRV_{n} (n=0..5) — PF[n] Multi-Driving Select (n = 0~5) 00: Level 0 01: Level 1 10: Level 2 11: Level 3
0xCC PF_DRV1 reset not defined
0xD0 PF_PULL0
  [2n+1:2n] PF_PULL_{n} (n=0..5) — PF[n] Pull-up/down Select (n = 0~5) 00: Pull-up/down disable 01: Pull-up 10: Pull-down 11: Reserved
0xD4 PF_PULL1 reset not defined
0xD8 PG_CFG0 reset 0x77777777
  [30:28] PG7_SELECT — 000: Input 001: Output 010: TS1_D3 011: CSI1_D3 100: UART3_RX 101: CSI0_D11 110: Reserved 111: IO Disable
    0=Input; 1=Output; 2=TS1_D3; 3=CSI1_D3; 4=UART3_RX; 5=CSI0_D11; 7=IO (IO Disable)
  [26:24] PG6_SELECT — 000: Input 001: Output 010: TS1_D2 011: CSI1_D2 100: UART3_TX 101: CSI0_D10 110: Reserved 111: IO Disable
    0=Input; 1=Output; 2=TS1_D2; 3=CSI1_D2; 4=UART3_TX; 5=CSI0_D10; 7=IO (IO Disable)
  [22:20] PG5_SELECT — 000: Input 001: Output 010: TS1_D1 011: CSI1_D1 100: SDC1_D3 101: CSI0_D9 110: Reserved 111: IO Disable
    0=Input; 1=Output; 2=TS1_D1; 3=CSI1_D1; 4=SDC1_D3; 5=CSI0_D9; 7=IO (IO Disable)
  [18:16] PG4_SELECT — 000: Input 001: Output 010: TS1_D0 011: CSI1_D0 100: SDC1_D2 101: CSI0_D8 110: Reserved 111: IO Disable
    0=Input; 1=Output; 2=TS1_D0; 3=CSI1_D0; 4=SDC1_D2; 5=CSI0_D8; 7=IO (IO Disable)
  [14:12] PG3_SELECT — 000: Input 001: Output 010: TS1_DVLD 011: CSI1_VSYNC 100: SDC1_D1 101: Reserved 110: Reserved 111: IO Disable
    0=Input; 1=Output; 2=TS1_DVLD; 3=CSI1_VSYNC; 4=SDC1_D1; 7=IO (IO Disable)
  [10:8] PG2_SELECT — 000: Input 001: Output 010: TS1_SYNC 011: CSI1_HSYNC 100: SDC1_D0 101: Reserved 110: Reserved 111: IO Disable
    0=Input; 1=Output; 2=TS1_SYNC; 3=CSI1_HSYNC; 4=SDC1_D0; 7=IO (IO Disable)
  [6:4] PG1_SELECT — 000: Input 001: Output 010: TS1_ERR 011: CSI1_MCLK 100: SDC1_CLK 101: Reserved 110: Reserved 111: IO Disable
    0=Input; 1=Output; 2=TS1_ERR; 3=CSI1_MCLK; 4=SDC1_CLK; 7=IO (IO Disable)
  [2:0] PG0_SELECT — 000: Input 001: Output 010: TS1_CLK 011: CSI1_PCLK 100: SDC1_CMD 101: Reserved 110: Reserved 111: IO Disable
    0=Input; 1=Output; 2=TS1_CLK; 3=CSI1_PCLK; 4=SDC1_CMD; 7=IO (IO Disable)
0xDC PG_CFG1 reset 0x7777
  [14:12] PG11_SELECT — 000: Input 001: Output 010: TS1_D7 011: CSI1_D7 100: UART4_RX 101: CSI0_D15 110: Reserved 111: IO Disable
    0=Input; 1=Output; 2=TS1_D7; 3=CSI1_D7; 4=UART4_RX; 5=CSI0_D15; 7=IO (IO Disable)
  [10:8] PG10_SELECT — 000: Input 001: Output 010: TS1_D6 011: CSI1_D6 100: UART4_TX 101: CSI0_D14 110: BIST_RESULT1 111: IO Disable
    0=Input; 1=Output; 2=TS1_D6; 3=CSI1_D6; 4=UART4_TX; 5=CSI0_D14; 6=BIST_RESULT1; 7=IO (IO Disable)
  [6:4] PG9_SELECT — 000: Input 001: Output 010: TS1_D5 011: CSI1_D5 100: UART3_CTS 101: CSI0_D13 110: BIST_RESULT0 111: IO Disable
    0=Input; 1=Output; 2=TS1_D5; 3=CSI1_D5; 4=UART3_CTS; 5=CSI0_D13; 6=BIST_RESULT0; 7=IO (IO Disable)
  [2:0] PG8_SELECT — 000: Input 001: Output 010: TS1_D4 011: CSI1_D4 100: UART3_RTS 101: CSI0_D12 110: Reserved 111: IO Disable
    0=Input; 1=Output; 2=TS1_D4; 3=CSI1_D4; 4=UART3_RTS; 5=CSI0_D12; 7=IO (IO Disable)
0xE0 PG_CFG2 reset not defined
0xE4 PG_CFG3 reset not defined
0xE8 PG_DAT
  [11:0] PG_DAT — If the port is configured as input, the corresponding bit is the pin state. If the port is configured as output, the pin state is the same as the corresponding bit. The read bit value is the value setup by software. If the port is configured as functional pin, the undefined value will be read.
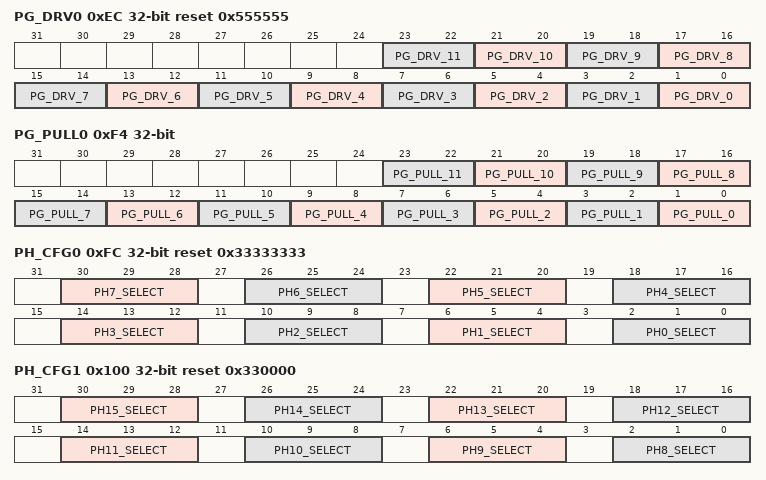
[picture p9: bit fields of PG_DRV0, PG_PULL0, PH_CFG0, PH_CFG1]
0xEC PG_DRV0 reset 0x555555
  [2n+1:2n] PG_DRV_{n} (n=0..11) — PG[n] Multi-Driving Select (n = 0~11) 00: Level 0 01: Level 1 10: Level 2 11: Level 3
0xF0 PG_DRV1 reset not defined
0xF4 PG_PULL0
  [2n+1:2n] PG_PULL_{n} (n=0..11) — PG[n] Pull-up/down Select (n = 0~11) 00: Pull-up/down disable 01: Pull-up 10: Pull-down 11: Reserved
0xF8 PG_PULL1 reset not defined
0xFC PH_CFG0 reset 0x33333333
  [30:28] PH7_SELECT — 000: Input 001: Output 010: LCD1_D7 011: IO Disable 100: UART5_RX 101: Reserved 110: EINT7 111: CSI1_D7
    0=Input; 1=Output; 2=LCD1_D7; 3=IO (IO Disable); 4=UART5_RX; 6=EINT7; 7=CSI1_D7
  [26:24] PH6_SELECT — 000: Input 001: Output 010: LCD1_D6 011: IO Disable 100: UART5_TX 101: Reserved 110: EINT6 111: CSI1_D6
    0=Input; 1=Output; 2=LCD1_D6; 3=IO (IO Disable); 4=UART5_TX; 6=EINT6; 7=CSI1_D6
  [22:20] PH5_SELECT — 000: Input 001: Output 010: LCD1_D5 011: IO Disable 100: UART4_RX 101: Reserved 110: EINT5 111: CSI1_D5
    0=Input; 1=Output; 2=LCD1_D5; 3=IO (IO Disable); 4=UART4_RX; 6=EINT5; 7=CSI1_D5
  [18:16] PH4_SELECT — 000: Input 001: Output 010: LCD1_D4 011: IO Disable 100: UART4_TX 101: Reserved 110: EINT4 111: CSI1_D4
    0=Input; 1=Output; 2=LCD1_D4; 3=IO (IO Disable); 4=UART4_TX; 6=EINT4; 7=CSI1_D4
  [14:12] PH3_SELECT — 000: Input 001: Output 010: LCD1_D3 011: IO Disable 100: UART3_CTS 101: Reserved 110: EINT3 111: CSI1_D3
    0=Input; 1=Output; 2=LCD1_D3; 3=IO (IO Disable); 4=UART3_CTS; 6=EINT3; 7=CSI1_D3
  [10:8] PH2_SELECT — 000: Input 001: Output 010: LCD1_D2 011: IO Disable 100: UART3_RTS 101: Reserved 110: EINT2 111: CSI1_D2
    0=Input; 1=Output; 2=LCD1_D2; 3=IO (IO Disable); 4=UART3_RTS; 6=EINT2; 7=CSI1_D2
  [6:4] PH1_SELECT — 000: Input 001: Output 010: LCD1_D1 011: IO Disable 100: UART3_RX 101: Reserved 110: EINT1 111: CSI1_D1
    0=Input; 1=Output; 2=LCD1_D1; 3=IO (IO Disable); 4=UART3_RX; 6=EINT1; 7=CSI1_D1
  [2:0] PH0_SELECT — 000: Input 001: Output 010: LCD1_D0 011: IO Disable 100: UART3_TX 101: Reserved 110: EINT0 111: CSI1_D0
    0=Input; 1=Output; 2=LCD1_D0; 3=IO (IO Disable); 4=UART3_TX; 6=EINT0; 7=CSI1_D0
0x100 PH_CFG1 reset 0x330000
  [30:28] PH15_SELECT — 000: Input 001: Output 010: LCD1_D15 011: ETXD2 100: KP_IN5 101: SMC_VPPPP 110: EINT15 111: CSI1_D15
    0=Input; 1=Output; 2=LCD1_D15; 3=ETXD2; 4=KP_IN5; 5=SMC_VPPPP; 6=EINT15; 7=CSI1_D15
  [26:24] PH14_SELECT — 000: Input 001: Output 010: LCD1_D14 011: ETXD3 100: KP_IN4 101: SMC_VPPEN 110: EINT14 111: CSI1_D14
    0=Input; 1=Output; 2=LCD1_D14; 3=ETXD3; 4=KP_IN4; 5=SMC_VPPEN; 6=EINT14; 7=CSI1_D14
  [22:20] PH13_SELECT — 000: Input 001: Output 010: LCD1_D13 011: IO Disable 100: PS2_SDA1 101: SMC_RST 110: EINT13 111: CSI1_D13
    0=Input; 1=Output; 2=LCD1_D13; 3=IO (IO Disable); 4=PS2_SDA1; 5=SMC_RST; 6=EINT13; 7=CSI1_D13
  [18:16] PH12_SELECT — 000: Input 001: Output 010: LCD1_D12 011: IO Disable 100: PS2_SCK1 101: Reserved 110: EINT12 111: CSI1_D12
    0=Input; 1=Output; 2=LCD1_D12; 3=IO (IO Disable); 4=PS2_SCK1; 6=EINT12; 7=CSI1_D12
  [14:12] PH11_SELECT — 000: Input 001: Output 010: LCD1_D11 011: ERXD0 100: KP_IN3 101: Reserved 110: EINT11 111: CSI1_D11
    0=Input; 1=Output; 2=LCD1_D11; 3=ERXD0; 4=KP_IN3; 6=EINT11; 7=CSI1_D11
  [10:8] PH10_SELECT — 000: Input 001: Output 010: LCD1_D10 011: ERXD1 100: KP_IN2 101: Reserved 110: EINT10 111: CSI1_D10
    0=Input; 1=Output; 2=LCD1_D10; 3=ERXD1; 4=KP_IN2; 6=EINT10; 7=CSI1_D10
  [6:4] PH9_SELECT — 000: Input 001: Output 010: LCD1_D9 011: ERXD2 100: KP_IN1 101: Reserved 110: EINT9 111: CSI1_D9
    0=Input; 1=Output; 2=LCD1_D9; 3=ERXD2; 4=KP_IN1; 6=EINT9; 7=CSI1_D9
  [2:0] PH8_SELECT — 000: Input 001: Output 010: LCD1_D8 011: ERXD3 100: KP_IN0 101: Reserved 110: EINT8 111: CSI1_D8
    0=Input; 1=Output; 2=LCD1_D8; 3=ERXD3; 4=KP_IN0; 6=EINT8; 7=CSI1_D8
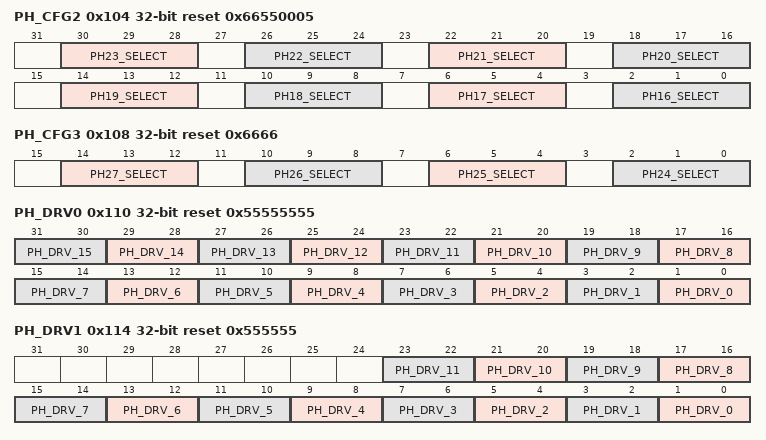
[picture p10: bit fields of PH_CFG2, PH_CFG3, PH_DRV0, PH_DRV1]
0x104 PH_CFG2 reset 0x66550005
  [30:28] PH23_SELECT — 000: Input 001: Output 010: LCD1_D23 011: ETXEN 100: KP_OUT3 101: SDC1_CLK 110: IO Disable 111: CSI1_D23
    0=Input; 1=Output; 2=LCD1_D23; 3=ETXEN; 4=KP_OUT3; 5=SDC1_CLK; 6=IO (IO Disable); 7=CSI1_D23
  [26:24] PH22_SELECT — 000: Input 001: Output 010: LCD1_D22 011: EMDIO 100: KP_OUT2 101: SDC1_CMD 110: IO Disable 111: CSI1_D22
    0=Input; 1=Output; 2=LCD1_D22; 3=EMDIO; 4=KP_OUT2; 5=SDC1_CMD; 6=IO (IO Disable); 7=CSI1_D22
  [22:20] PH21_SELECT — 000: Input 001: Output 010: LCD1_D21 011: EMDC 100: Reserved 101: IO Disable 110: EINT21 111: CSI1_D21
    0=Input; 1=Output; 2=LCD1_D21; 3=EMDC; 5=IO (IO Disable); 6=EINT21; 7=CSI1_D21
  [18:16] PH20_SELECT — 000: Input 001: Output 010: LCD1_D20 011: ERXDV 100: Reserved 101: IO Disable 110: EINT20 111: CSI1_D20
    0=Input; 1=Output; 2=LCD1_D20; 3=ERXDV; 5=IO (IO Disable); 6=EINT20; 7=CSI1_D20
  [14:12] PH19_SELECT — 000: Input 001: Output 010: LCD1_D19 011: ERXERR 100: KP_OUT1 101: SMC_SDA 110: EINT19 111: CSI1_D19
    0=Input; 1=Output; 2=LCD1_D19; 3=ERXERR; 4=KP_OUT1; 5=SMC_SDA; 6=EINT19; 7=CSI1_D19
  [10:8] PH18_SELECT — 000: Input 001: Output 010: LCD1_D18 011: ERXCK 100: KP_OUT0 101: SMC_SCK 110: EINT18 111: CSI1_D18
    0=Input; 1=Output; 2=LCD1_D18; 3=ERXCK; 4=KP_OUT0; 5=SMC_SCK; 6=EINT18; 7=CSI1_D18
  [6:4] PH17_SELECT — 000: Input 001: Output 010: LCD1_D17 011: ETXD0 100: KP_IN7 101: SMC_VCCEN 110: EINT17 111: CSI1_D17
    0=Input; 1=Output; 2=LCD1_D17; 3=ETXD0; 4=KP_IN7; 5=SMC_VCCEN; 6=EINT17; 7=CSI1_D17
  [2:0] PH16_SELECT — 000: Input 001: Output 010: LCD1_D16 011: ETXD1 100: KP_IN6 101: SMC_DET 110: EINT16 111: CSI1_D16
    0=Input; 1=Output; 2=LCD1_D16; 3=ETXD1; 4=KP_IN6; 5=SMC_DET; 6=EINT16; 7=CSI1_D16
0x108 PH_CFG3 reset 0x6666
  [14:12] PH27_SELECT — 000: Input 001: Output 010: LCD1_VSYNC 011: ETXERR 100: KP_OUT7 101: SDC1_D3 110: IO Disable 111: CSI1_VSYNC
    0=Input; 1=Output; 2=LCD1_VSYNC; 3=ETXERR; 4=KP_OUT7; 5=SDC1_D3; 6=IO (IO Disable); 7=CSI1_VSYNC
  [10:8] PH26_SELECT — 000: Input 001: Output 010: LCD1_HSYNC 011: ECOL 100: KP_OUT6 101: SDC1_D2 110: IO Disable 111: CSI1_HSYNC
    0=Input; 1=Output; 2=LCD1_HSYNC; 3=ECOL; 4=KP_OUT6; 5=SDC1_D2; 6=IO (IO Disable); 7=CSI1_HSYNC
  [6:4] PH25_SELECT — 000: Input 001: Output 010: LCD1_DE 011: ECRS 100: KP_OUT5 101: SDC1_D1 110: IO Disable 111: CSI1_FIELD
    0=Input; 1=Output; 2=LCD1_DE; 3=ECRS; 4=KP_OUT5; 5=SDC1_D1; 6=IO (IO Disable); 7=CSI1_FIELD
  [2:0] PH24_SELECT — 000: Input 001: Output 010: LCD1_CLK 011: ETXCK 100: KP_OUT4 101: SDC1_D0 110: IO Disable 111: CSI1_PCLK
    0=Input; 1=Output; 2=LCD1_CLK; 3=ETXCK; 4=KP_OUT4; 5=SDC1_D0; 6=IO (IO Disable); 7=CSI1_PCLK
0x10C PH_DAT
  [27:0] PH_DAT — If the port is configured as input, the corresponding bit is the pin state. If the port is configured as output, the pin state is the same as the corresponding bit. The read bit value is the value setup by software. If the port is configured as functional pin, the undefined value will be read.
0x110 PH_DRV0 reset 0x55555555
  [2n+1:2n] PH_DRV_{n} (n=0..15) — PH[n] Multi-Driving Select (n = 0~15) 00: Level 0 01: Level 1 10: Level 2 11: Level 3
0x114 PH_DRV1 reset 0x555555
  [2n+1:2n] PH_DRV_{n} (n=0..11) — PH[n] Multi-Driving Select (n = 16~27) 00: Level 0 01: Level 1 10: Level 2 11: Level 3
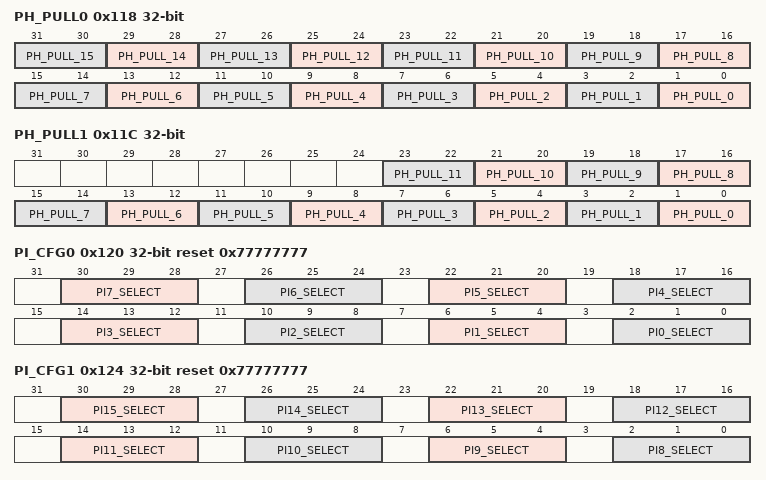
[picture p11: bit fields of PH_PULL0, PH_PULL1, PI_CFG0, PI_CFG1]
0x118 PH_PULL0
  [2n+1:2n] PH_PULL_{n} (n=0..15) — PH[n] Pull-up/down Select (n = 0~15) 00: Pull-up/down disable 01: Pull-up 10: Pull-down 11: Reserved
0x11C PH_PULL1
  [2n+1:2n] PH_PULL_{n} (n=0..11) — PH[n] Pull-up/down Select (n = 16~27)00: Pull-up/down disable 01: Pull-up 10: Pull-down 11: Reserved
0x120 PI_CFG0 reset 0x77777777
  [30:28] PI7_SELECT — 000: Input 001: Output 010: SDC3_D1 011: Reserved 100: Reserved 101: Reserved 110: Reserved 111: IO Disable
    0=Input; 1=Output; 2=SDC3_D1; 7=IO (IO Disable)
  [26:24] PI6_SELECT — 000: Input 001: Output 010: SDC3_D0 011: Reserved 100: Reserved 101: Reserved 110: Reserved 111: IO Disable
    0=Input; 1=Output; 2=SDC3_D0; 7=IO (IO Disable)
  [22:20] PI5_SELECT — 000: Input 001: Output 010: SDC3_CLK 011: Reserved 100: Reserved 101: Reserved 110: Reserved 111: IO Disable
    0=Input; 1=Output; 2=SDC3_CLK; 7=IO (IO Disable)
  [18:16] PI4_SELECT — 000: Input 001: Output 010: SDC3_CMD 011: Reserved 100: Reserved 101: Reserved 110: Reserved 111: IO Disable
    0=Input; 1=Output; 2=SDC3_CMD; 7=IO (IO Disable)
  [14:12] PI3_SELECT — 000: Input 001: Output 010: PWM1 011: TWI4_SDA 100: Reserved 101: Reserved 110: Reserved 111: IO Disable
    0=Input; 1=Output; 2=PWM1; 3=TWI4_SDA; 7=IO (IO Disable)
  [10:8] PI2_SELECT — 000: Input 001: Output 010: Reserved 011: TWI4_SCK 100: Reserved 101: Reserved 110: Reserved 111: IO Disable
    0=Input; 1=Output; 3=TWI4_SCK; 7=IO (IO Disable)
  [6:4] PI1_SELECT — 000: Input 001: Output 010: Reserved 011: TWI3_SDA 100: Reserved 101: Reserved 110: Reserved 111: IO Disable
    0=Input; 1=Output; 3=TWI3_SDA; 7=IO (IO Disable)
  [2:0] PI0_SELECT — 000: Input 001: Output 010: Reserved 011: TWI3_SCK 100: Reserved 101: Reserved 110: Reserved 111: IO Disable
    0=Input; 1=Output; 3=TWI3_SCK; 7=IO (IO Disable)
0x124 PI_CFG1 reset 0x77777777
  [30:28] PI15_SELECT — 000: Input 001: Output 010: SPI1_CS1 011: PS2_SDA1 100: TCLKIN1 101: Reserved 110: EINT27 111: IO Disable
    0=Input; 1=Output; 2=SPI1_CS1; 3=PS2_SDA1; 4=TCLKIN1; 6=EINT27; 7=IO (IO Disable)
  [26:24] PI14_SELECT — 000: Input 001: Output 010: SPI0_CS1 011: PS2_SCK1 100: TCLKIN0 101: Reserved 110: EINT26 111: IO Disable
    0=Input; 1=Output; 2=SPI0_CS1; 3=PS2_SCK1; 4=TCLKIN0; 6=EINT26; 7=IO (IO Disable)
  [22:20] PI13_SELECT — 000: Input 001: Output 010: SPI0_MISO 011: UART6_RX 100: CLK_OUT_B 101: Reserved 110: EINT25 111: IO Disable
    0=Input; 1=Output; 2=SPI0_MISO; 3=UART6_RX; 4=CLK_OUT_B; 6=EINT25; 7=IO (IO Disable)
  [18:16] PI12_SELECT — 000: Input 001: Output 010: SPI0_MOSI 011: UART6_TX 100: CLK_OUT_A 101: Reserved 110: EINT24 111: IO Disable
    0=Input; 1=Output; 2=SPI0_MOSI; 3=UART6_TX; 4=CLK_OUT_A; 6=EINT24; 7=IO (IO Disable)
  [14:12] PI11_SELECT — 000: Input 001: Output 010: SPI0_CLK 011: UART5_RX 100: Reserved 101: Reserved 110: EINT23 111: IO Disable
    0=Input; 1=Output; 2=SPI0_CLK; 3=UART5_RX; 6=EINT23; 7=IO (IO Disable)
  [10:8] PI10_SELECT — 000: Input 001: Output 010: SPI0_CS0 011: UART5_TX 100: Reserved 101: Reserved 110: EINT22 111: IO Disable
    0=Input; 1=Output; 2=SPI0_CS0; 3=UART5_TX; 6=EINT22; 7=IO (IO Disable)
  [6:4] PI9_SELECT — 000: Input 001: Output 010: SDC3_D3 011: Reserved 100: Reserved 101: Reserved 110: Reserved 111: IO Disable
    0=Input; 1=Output; 2=SDC3_D3; 7=IO (IO Disable)
  [2:0] PI8_SELECT — 000: Input 001: Output 010: SDC3_D2 011: Reserved 100: Reserved 101: Reserved 110: Reserved 111: IO Disable
    0=Input; 1=Output; 2=SDC3_D2; 7=IO (IO Disable)
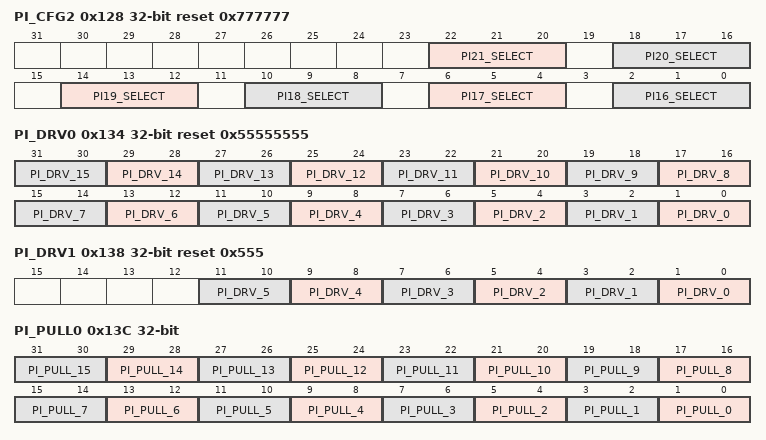
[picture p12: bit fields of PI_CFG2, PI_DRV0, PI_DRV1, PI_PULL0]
0x128 PI_CFG2 reset 0x777777
  [22:20] PI21_SELECT — 000: Input 001: Output 010: PS2_SDA0 011: UART7_RX 100: Reserved 101: Reserved 110: PWM3 111: IO Disable
    0=Input; 1=Output; 2=PS2_SDA0; 3=UART7_RX; 6=PWM3; 7=IO (IO Disable)
  [18:16] PI20_SELECT — 000: Input 001: Output 010: PS2_SCK0 011: UART7_TX 100: Reserved 101: Reserved 110: PWM2 111: IO Disable
    0=Input; 1=Output; 2=PS2_SCK0; 3=UART7_TX; 6=PWM2; 7=IO (IO Disable)
  [14:12] PI19_SELECT — 000: Input 001: Output 010: SPI1_MISO 011: UART2_RX 100: Reserved 101: Reserved 110: EINT31 111: IO Disable
    0=Input; 1=Output; 2=SPI1_MISO; 3=UART2_RX; 6=EINT31; 7=IO (IO Disable)
  [10:8] PI18_SELECT — 000: Input 001: Output 010: SPI1_MOSI 011: UART2_TX 100: Reserved 101: Reserved 110: EINT30 111: IO Disable
    0=Input; 1=Output; 2=SPI1_MOSI; 3=UART2_TX; 6=EINT30; 7=IO (IO Disable)
  [6:4] PI17_SELECT — 000: Input 001: Output 010: SPI1_CLK 011: UART2_CTS 100: Reserved 101: Reserved 110: EINT29 111: IO Disable
    0=Input; 1=Output; 2=SPI1_CLK; 3=UART2_CTS; 6=EINT29; 7=IO (IO Disable)
  [2:0] PI16_SELECT — 000: Input 001: Output 010: SPI1_CS0 011: UART2_RTS 100: Reserved 101: Reserved 110: EINT28 111: IO Disable
    0=Input; 1=Output; 2=SPI1_CS0; 3=UART2_RTS; 6=EINT28; 7=IO (IO Disable)
0x12C PI_CFG3 reset not defined
0x130 PI_DAT
  [21:0] PI_DAT — If the port is configured as input, the corresponding bit is the pin state. If the port is configured as output, the pin state is the same as the corresponding bit. The read bit value is the value setup by software. If the port is configured as functional pin, the undefined value will be read.
0x134 PI_DRV0 reset 0x55555555
  [2n+1:2n] PI_DRV_{n} (n=0..15) — PI[n] Multi-Driving Select (n = 0~15) 00: Level 0 01: Level 1 10: Level 2 11: Level 3
0x138 PI_DRV1 reset 0x555
  [2n+1:2n] PI_DRV_{n} (n=0..5) — PI[n] Multi-Driving Select (n = 16~21) 00: Level 0 01: Level 1 10: Level 2 11: Level 3
0x13C PI_PULL0
  [2n+1:2n] PI_PULL_{n} (n=0..15) — PI[n] Pull-up/down Select (n = 0~15) 00: Pull-up/down disable 01: Pull-up 10: Pull-down 11: Reserved
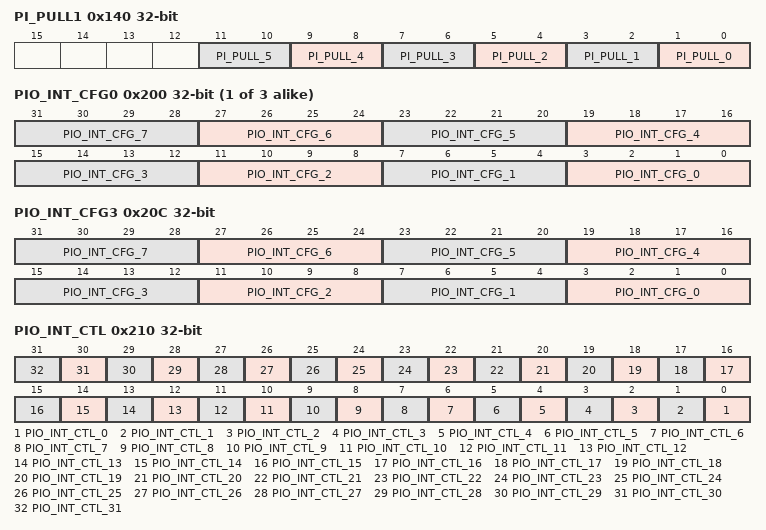
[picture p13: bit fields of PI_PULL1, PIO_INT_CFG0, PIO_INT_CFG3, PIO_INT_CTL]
0x140 PI_PULL1
  [2n+1:2n] PI_PULL_{n} (n=0..5) — PI[n] Pull-up/down Select (n = 16~21) 00: Pull-up/down disable 01: Pull-up 10: Pull-down 11: Reserved
{0x200+4i} PIO_INT_CFG{i} (i=0..2) — PIO Interrupt Configure Register {i}
  [4n+3:4n] PIO_INT_CFG_{n} (n=0..7) — External INTn Mode (n = {8i}~{8i+7}) 0000: Positive Edge 0001: Negative Edge 0010: High Level 0011: Low Level 0100: Double Edge (Positive/ Negative) Others: Reserved
0x20C PIO_INT_CFG3 — PIO Interrupt Configure Register 3
  [4n+3:4n] PIO_INT_CFG_{n} (n=0..7) — External INTn Mode(n=24~31) 0: Positive Edge 1: Negative Edge
0x210 PIO_INT_CTL — PIO Interrupt Control Register
  [n] PIO_INT_CTL_{n} (n=0..31) — External INTn Enable (n = 0~31) 0: Disable 1: Enable
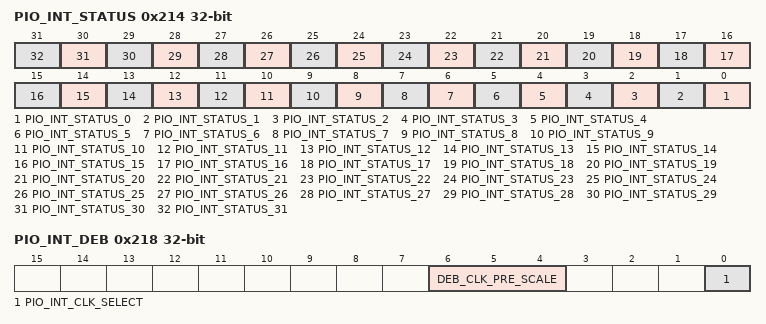
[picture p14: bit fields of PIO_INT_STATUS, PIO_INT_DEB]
0x214 PIO_INT_STATUS
  [n] PIO_INT_STATUS_{n} (n=0..31) — External INTn Pending Bit (n = 0~31) 0: No IRQ pending 1: IRQ pending Write `1` to clear it
0x218 PIO_INT_DEB — PIO Interrupt Debounce Register
  [6:4] DEB_CLK_PRE_SCALE — Debounce Clock Pre-scale n The selected clock source is prescaled by 2^n.
  [0] PIO_INT_CLK_SELECT — PIO Interrupt Clock Select 0: LOSC 32KHz 1: HOSC 24MHz
    0=LOSC (LOSC 32KHz); 1=HOSC (HOSC 24MHz)
